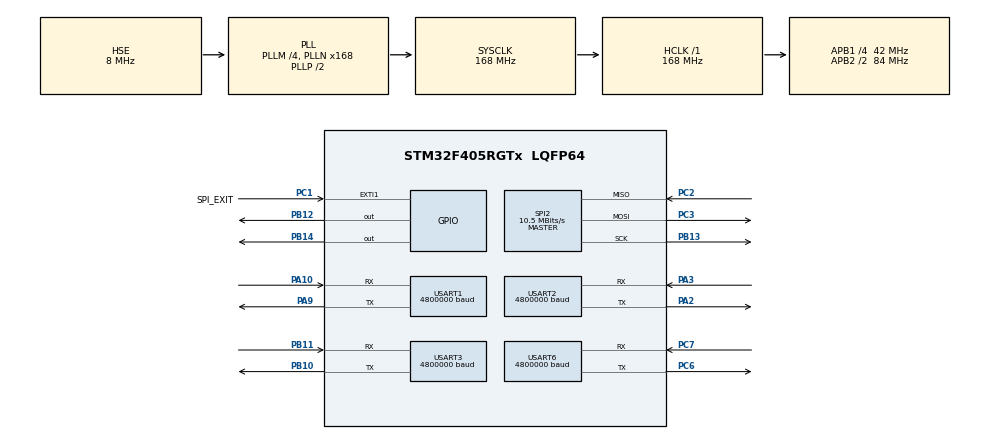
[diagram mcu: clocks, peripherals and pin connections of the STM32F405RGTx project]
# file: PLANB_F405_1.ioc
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Dma.Request0=USART1_RX
Dma.Request1=USART2_RX
Dma.Request2=USART3_RX
Dma.Request3=USART6_RX
Dma.Request4=SPI2_RX
Dma.Request5=SPI2_TX
Dma.SPI2_RX.4.Direction=DMA_PERIPH_TO_MEMORY
Dma.SPI2_RX.4.FIFOMode=DMA_FIFOMODE_DISABLE
Dma.SPI2_RX.4.Instance=DMA1_Stream3
Dma.SPI2_RX.4.MemDataAlignment=DMA_MDATAALIGN_BYTE
Dma.SPI2_RX.4.MemInc=DMA_MINC_ENABLE
Dma.SPI2_RX.4.Mode=DMA_NORMAL
Dma.SPI2_RX.4.PeriphDataAlignment=DMA_PDATAALIGN_BYTE
Dma.SPI2_RX.4.PeriphInc=DMA_PINC_DISABLE
Dma.SPI2_RX.4.Priority=DMA_PRIORITY_HIGH
Dma.SPI2_TX.5.Direction=DMA_MEMORY_TO_PERIPH
Dma.SPI2_TX.5.FIFOMode=DMA_FIFOMODE_DISABLE
Dma.SPI2_TX.5.Instance=DMA1_Stream4
Dma.SPI2_TX.5.MemDataAlignment=DMA_MDATAALIGN_BYTE
Dma.SPI2_TX.5.MemInc=DMA_MINC_ENABLE
Dma.SPI2_TX.5.Mode=DMA_NORMAL
Dma.SPI2_TX.5.PeriphDataAlignment=DMA_PDATAALIGN_BYTE
Dma.SPI2_TX.5.PeriphInc=DMA_PINC_DISABLE
Dma.SPI2_TX.5.Priority=DMA_PRIORITY_MEDIUM
Dma.USART1_RX.0.Direction=DMA_PERIPH_TO_MEMORY
Dma.USART1_RX.0.FIFOMode=DMA_FIFOMODE_DISABLE
Dma.USART1_RX.0.Instance=DMA2_Stream2
Dma.USART1_RX.0.MemDataAlignment=DMA_MDATAALIGN_BYTE
Dma.USART1_RX.0.MemInc=DMA_MINC_ENABLE
Dma.USART1_RX.0.Mode=DMA_NORMAL
Dma.USART1_RX.0.PeriphDataAlignment=DMA_PDATAALIGN_BYTE
Dma.USART1_RX.0.PeriphInc=DMA_PINC_DISABLE
Dma.USART1_RX.0.Priority=DMA_PRIORITY_LOW
Dma.USART2_RX.1.Direction=DMA_PERIPH_TO_MEMORY
Dma.USART2_RX.1.FIFOMode=DMA_FIFOMODE_DISABLE
Dma.USART2_RX.1.Instance=DMA1_Stream5
Dma.USART2_RX.1.MemDataAlignment=DMA_MDATAALIGN_BYTE
Dma.USART2_RX.1.MemInc=DMA_MINC_ENABLE
Dma.USART2_RX.1.Mode=DMA_NORMAL
Dma.USART2_RX.1.PeriphDataAlignment=DMA_PDATAALIGN_BYTE
Dma.USART2_RX.1.PeriphInc=DMA_PINC_DISABLE
Dma.USART2_RX.1.Priority=DMA_PRIORITY_LOW
Dma.USART3_RX.2.Direction=DMA_PERIPH_TO_MEMORY
Dma.USART3_RX.2.FIFOMode=DMA_FIFOMODE_DISABLE
Dma.USART3_RX.2.Instance=DMA1_Stream1
Dma.USART3_RX.2.MemDataAlignment=DMA_MDATAALIGN_BYTE
Dma.USART3_RX.2.MemInc=DMA_MINC_ENABLE
Dma.USART3_RX.2.Mode=DMA_NORMAL
Dma.USART3_RX.2.PeriphDataAlignment=DMA_PDATAALIGN_BYTE
Dma.USART3_RX.2.PeriphInc=DMA_PINC_DISABLE
Dma.USART3_RX.2.Priority=DMA_PRIORITY_LOW
Dma.USART6_RX.3.Direction=DMA_PERIPH_TO_MEMORY
Dma.USART6_RX.3.FIFOMode=DMA_FIFOMODE_DISABLE
Dma.USART6_RX.3.Instance=DMA2_Stream1
Dma.USART6_RX.3.MemDataAlignment=DMA_MDATAALIGN_BYTE
Dma.USART6_RX.3.MemInc=DMA_MINC_ENABLE
Dma.USART6_RX.3.Mode=DMA_NORMAL
Dma.USART6_RX.3.PeriphDataAlignment=DMA_PDATAALIGN_BYTE
Dma.USART6_RX.3.PeriphInc=DMA_PINC_DISABLE
Dma.USART6_RX.3.Priority=DMA_PRIORITY_LOW
Mcu.Family=STM32F4
Mcu.Name=STM32F405RGTx
Mcu.Package=LQFP64
NVIC.DMA1_Stream1_IRQn=true\:0\:0\:false\:false\:false\:false\:true\:true
NVIC.DMA1_Stream3_IRQn=true\:0\:0\:false\:false\:false\:false\:true\:true
NVIC.DMA1_Stream4_IRQn=true\:0\:0\:false\:false\:false\:false\:true\:true
NVIC.DMA1_Stream5_IRQn=true\:0\:0\:false\:false\:false\:false\:true\:true
NVIC.DMA2_Stream1_IRQn=true\:0\:0\:false\:false\:false\:false\:true\:true
NVIC.DMA2_Stream2_IRQn=true\:0\:0\:false\:false\:false\:false\:true\:true
NVIC.EXTI1_IRQn=true\:0\:0\:false\:false\:true\:true\:true\:true
NVIC.PriorityGroup=NVIC_PRIORITYGROUP_4
NVIC.SPI2_IRQn=true\:2\:0\:true\:false\:true\:true\:true\:true
NVIC.TIM4_IRQn=true\:4\:0\:true\:false\:true\:true\:true\:true
NVIC.USART1_IRQn=true\:3\:0\:true\:false\:false\:true\:true\:true
NVIC.USART2_IRQn=true\:3\:0\:true\:false\:false\:true\:true\:true
NVIC.USART3_IRQn=true\:3\:0\:true\:false\:false\:true\:true\:true
NVIC.USART6_IRQn=true\:3\:0\:true\:false\:false\:true\:true\:true
PA10.Mode=Asynchronous
PA10.Signal=USART1_RX
PA13.Mode=Serial_Wire
PA13.Signal=SYS_JTMS-SWDIO
PA14.Mode=Serial_Wire
PA14.Signal=SYS_JTCK-SWCLK
PA2.Mode=Asynchronous
PA2.Signal=USART2_TX
PA3.Mode=Asynchronous
PA3.Signal=USART2_RX
PA9.Mode=Asynchronous
PA9.Signal=USART1_TX
PB10.Mode=Asynchronous
PB10.Signal=USART3_TX
PB11.Mode=Asynchronous
PB11.Signal=USART3_RX
PB12.GPIO_PuPd=GPIO_NOPULL
PB12.GPIO_Speed=GPIO_SPEED_FREQ_VERY_HIGH
PB12.PinState=GPIO_PIN_RESET
PB12.Signal=GPIO_Output
PB13.Mode=Full_Duplex_Master
PB13.Signal=SPI2_SCK
PB14.PinState=GPIO_PIN_SET
PB14.Signal=GPIO_Output
PC1.GPIO_Label=SPI_EXIT
PC1.GPIO_ModeDefaultEXTI=GPIO_MODE_IT_RISING
PC1.GPIO_PuPd=GPIO_PULLUP
PC1.Signal=GPXTI1
PC2.Mode=Full_Duplex_Master
PC2.Signal=SPI2_MISO
PC3.Mode=Full_Duplex_Master
PC3.Signal=SPI2_MOSI
PC6.Mode=Asynchronous
PC6.Signal=USART6_TX
PC7.Mode=Asynchronous
PC7.Signal=USART6_RX
PH0-OSC_IN.Mode=HSE-External-Oscillator
PH0-OSC_IN.Signal=RCC_OSC_IN
PH1-OSC_OUT.Mode=HSE-External-Oscillator
PH1-OSC_OUT.Signal=RCC_OSC_OUT
ProjectManager.HeapSize=0x200
ProjectManager.StackSize=0x400
ProjectManager.TargetToolchain=Makefile
RCC.48MHZClocksFreq_Value=84000000
RCC.AHBFreq_Value=168000000
RCC.APB1CLKDivider=RCC_HCLK_DIV4
RCC.APB1Freq_Value=42000000
RCC.APB1TimFreq_Value=84000000
RCC.APB2CLKDivider=RCC_HCLK_DIV2
RCC.APB2Freq_Value=84000000
RCC.APB2TimFreq_Value=168000000
RCC.CortexFreq_Value=168000000
RCC.HCLKFreq_Value=168000000
RCC.HSE_VALUE=8000000
RCC.HSI_VALUE=16000000
RCC.LSE_VALUE=32768
RCC.PLLM=4
RCC.PLLN=168
RCC.PLLSourceVirtual=RCC_PLLSOURCE_HSE
RCC.SYSCLKFreq_VALUE=168000000
RCC.SYSCLKSource=RCC_SYSCLKSOURCE_PLLCLK
RCC.VCOOutputFreq_Value=336000000
SPI2.BaudRatePrescaler=SPI_BAUDRATEPRESCALER_4
SPI2.CLKPolarity=SPI_POLARITY_HIGH
SPI2.CalculateBaudRate=10.5 MBits/s
SPI2.Direction=SPI_DIRECTION_2LINES
SPI2.Mode=SPI_MODE_MASTER
SPI2.VirtualType=VM_MASTER
TIM4.Channel-PWM\ Generation1\ No\ Output=TIM_CHANNEL_1
TIM4.Period=2999
TIM4.Prescaler=55
USART1.BaudRate=4800000
USART1.VirtualMode=VM_ASYNC
USART2.BaudRate=4800000
USART2.OverSampling=UART_OVERSAMPLING_8
USART2.VirtualMode=VM_ASYNC
USART3.BaudRate=4800000
USART3.OverSampling=UART_OVERSAMPLING_8
USART3.VirtualMode=VM_ASYNC
USART6.BaudRate=4800000
USART6.VirtualMode=VM_ASYNC
VP_TIM4_VS_no_output1.Mode=PWM Generation1 No Output
board=custom

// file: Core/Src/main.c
/* USER CODE BEGIN Header */
/**
 ******************************************************************************
 * @file           : main.c
 * @brief          : Main program body
 ******************************************************************************
 * @attention
 *
 * Copyright (c) 2024 STMicroelectronics.
 * All rights reserved.
 *
 * This software is licensed under terms that can be found in the LICENSE file
 * in the root directory of this software component.
 * If no LICENSE file comes with this software, it is provided AS-IS.
 *
 ******************************************************************************
 */
/* USER CODE END Header */
#include "main.h"
#include "dma.h"
#include "spi.h"
#include "tim.h"
#include "usart.h"
#include "gpio.h"

/* USER CODE BEGIN Includes */
#include "unitreeA1_cmd.h"
#include "unitreeA1_recv.h"
#include "spi_deal.h"
/* USER CODE END Includes */

void SystemClock_Config(void);

int main(void)
{

  /* MCU Configuration--------------------------------------------------------*/

  /* Reset of all peripherals, Initializes the Flash interface and the Systick. */
  HAL_Init();

  /* Configure the system clock */
  SystemClock_Config();

  /* Initialize all configured peripherals */
  MX_GPIO_Init();
  MX_DMA_Init();
  MX_SPI2_Init();
  MX_USART1_UART_Init();
  MX_USART2_UART_Init();
  MX_USART3_UART_Init();
  MX_USART6_UART_Init();
  MX_TIM4_Init();
  /* USER CODE BEGIN 2 */

  // 清除定时器初始化过程中的更新中断标志，避免定时器一启动就中断
  __HAL_TIM_CLEAR_IT(&htim4, TIM_IT_UPDATE);
  // 使能定时器3更新中断并启动定时器
  HAL_TIM_Base_Start_IT(&htim4);
  remote_control_init();
  // EcatChat_Init();

  /* USER CODE END 2 */

  /* Infinite loop */
  /* USER CODE BEGIN WHILE */
  while (1)
  {
    //unitreeA1_enable(3,1);
    SPI_TRANSMIT(0, 0);
    SPI_TRANSMIT(0, 1);
    SPI_TRANSMIT(0, 2);
    SPI_TRANSMIT(1, 0);
    SPI_TRANSMIT(1, 1);
    SPI_TRANSMIT(1, 2);

    // sendToEcat(0);
    // SPI_TRANSMIT(1,1);
    // SPI_TRANSMIT(1,2);
    // SPI_TRANSMIT(2,0);
    // SPI_TRANSMIT(2,1);
    // SPI_TRANSMIT(2,2);
    // SPI_TRANSMIT(3,0);
    // SPI_TRANSMIT(3,1);
    // SPI_TRANSMIT(3,2);

    // unitreeA1_tx(1,1);
    // unitreeA1_tx(1,2);
    // unitreeA1_tx(2,0);
    // unitreeA1_tx(2,1);
    // unitreeA1_tx(2,2);
    // unitreeA1_tx(3,0);
    // unitreeA1_tx(3,1);
    // unitreeA1_tx(3,2);

    /* USER CODE END WHILE */

  }
}

void SystemClock_Config(void)
{
  RCC_OscInitTypeDef RCC_OscInitStruct = {0};
  RCC_ClkInitTypeDef RCC_ClkInitStruct = {0};

  /** Configure the main internal regulator output voltage
  */
  __HAL_RCC_PWR_CLK_ENABLE();
  __HAL_PWR_VOLTAGESCALING_CONFIG(PWR_REGULATOR_VOLTAGE_SCALE1);

  /** Initializes the RCC Oscillators according to the specified parameters
  * in the RCC_OscInitTypeDef structure.
  */
  RCC_OscInitStruct.OscillatorType = RCC_OSCILLATORTYPE_HSE;
  RCC_OscInitStruct.HSEState = RCC_HSE_ON;
  RCC_OscInitStruct.PLL.PLLState = RCC_PLL_ON;
  RCC_OscInitStruct.PLL.PLLSource = RCC_PLLSOURCE_HSE;
  RCC_OscInitStruct.PLL.PLLM = 4;
  RCC_OscInitStruct.PLL.PLLN = 168;
  RCC_OscInitStruct.PLL.PLLP = RCC_PLLP_DIV2;
  RCC_OscInitStruct.PLL.PLLQ = 4;
  if (HAL_RCC_OscConfig(&RCC_OscInitStruct) != HAL_OK)
  {
    Error_Handler();
  }

  /** Initializes the CPU, AHB and APB buses clocks
  */
  RCC_ClkInitStruct.ClockType = RCC_CLOCKTYPE_HCLK|RCC_CLOCKTYPE_SYSCLK
                              |RCC_CLOCKTYPE_PCLK1|RCC_CLOCKTYPE_PCLK2;
  RCC_ClkInitStruct.SYSCLKSource = RCC_SYSCLKSOURCE_PLLCLK;
  RCC_ClkInitStruct.AHBCLKDivider = RCC_SYSCLK_DIV1;
  RCC_ClkInitStruct.APB1CLKDivider = RCC_HCLK_DIV4;
  RCC_ClkInitStruct.APB2CLKDivider = RCC_HCLK_DIV2;

  if (HAL_RCC_ClockConfig(&RCC_ClkInitStruct, FLASH_LATENCY_5) != HAL_OK)
  {
    Error_Handler();
  }
}

void Error_Handler(void)
{
  __disable_irq();
  while (1)
  {
  }
}
